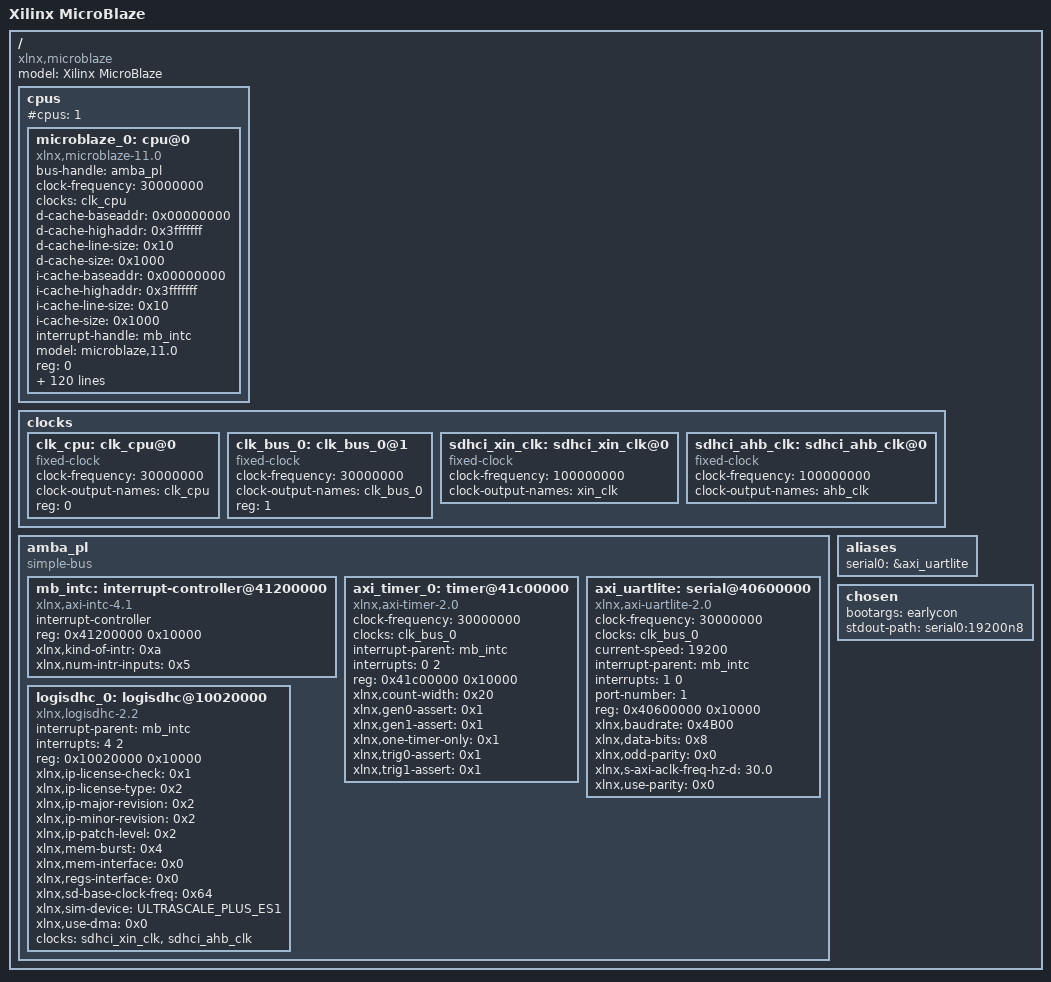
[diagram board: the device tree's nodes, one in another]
/*
 * This file is derived from the one which is automatically generated
 * from Xilinx Tools.
 * Version: XSCT
 * Today is: Fri May 10 15:45:01 2024
 */


/dts-v1/;
/ {
	#address-cells = <1>;
	#size-cells = <1>;
	compatible = "xlnx,microblaze";
	model = "Xilinx MicroBlaze";
	cpus {
		bootph-all;
		#address-cells = <1>;
		#cpus = <1>;
		#size-cells = <0>;
		microblaze_0: cpu@0 {
			bootph-all;
			bus-handle = <&amba_pl>;
			clock-frequency = <30000000>;
			clocks = <&clk_cpu>;
			compatible = "xlnx,microblaze-11.0";
			d-cache-baseaddr = <0x00000000>;
			d-cache-highaddr = <0x3fffffff>;
			d-cache-line-size = <0x10>;
			d-cache-size = <0x1000>;
			device_type = "cpu";
			i-cache-baseaddr = <0x00000000>;
			i-cache-highaddr = <0x3fffffff>;
			i-cache-line-size = <0x10>;
			i-cache-size = <0x1000>;
			interrupt-handle = <&mb_intc>;
			model = "microblaze,11.0";
			reg = <0>;
			timebase-frequency = <30000000>;
			xlnx,addr-size = <0x24>;
			xlnx,addr-tag-bits = <0x0>;
			xlnx,allow-dcache-wr = <0x1>;
			xlnx,allow-icache-wr = <0x1>;
			xlnx,area-optimized = <0x1>;
			xlnx,async-interrupt = <0x1>;
			xlnx,async-wakeup = <0x3>;
			xlnx,avoid-primitives = <0x0>;
			xlnx,base-vectors = <0x00000000 0x00000000>;
			xlnx,branch-target-cache-size = <0x0>;
			xlnx,cache-byte-size = <0x1000>;
			xlnx,d-axi = <0x1>;
			xlnx,d-lmb = <0x1>;
			xlnx,d-lmb-mon = <0x0>;
			xlnx,d-lmb-protocol = <0x0>;
			xlnx,daddr-size = <0x24>;
			xlnx,data-size = <0x20>;
			xlnx,dc-axi-mon = <0x0>;
			xlnx,dcache-addr-tag = <0x0>;
			xlnx,dcache-always-used = <0x1>;
			xlnx,dcache-byte-size = <0x1000>;
			xlnx,dcache-data-width = <0x0>;
			xlnx,dcache-force-tag-lutram = <0x0>;
			xlnx,dcache-line-len = <0x4>;
			xlnx,dcache-use-writeback = <0x0>;
			xlnx,dcache-victims = <0x0>;
			xlnx,debug-counter-width = <0x20>;
			xlnx,debug-enabled = <0x1>;
			xlnx,debug-event-counters = <0x5>;
			xlnx,debug-external-trace = <0x0>;
			xlnx,debug-interface = <0x0>;
			xlnx,debug-latency-counters = <0x1>;
			xlnx,debug-profile-size = <0x0>;
			xlnx,debug-trace-async-reset = <0x0>;
			xlnx,debug-trace-size = <0x2000>;
			xlnx,div-zero-exception = <0x0>;
			xlnx,dp-axi-mon = <0x0>;
			xlnx,dynamic-bus-sizing = <0x0>;
			xlnx,ecc-use-ce-exception = <0x0>;
			xlnx,edge-is-positive = <0x1>;
			xlnx,enable-discrete-ports = <0x0>;
			xlnx,endianness = <0x1>;
			xlnx,fault-tolerant = <0x0>;
			xlnx,fpu-exception = <0x0>;
			xlnx,freq = <0x1c9c380>;
			xlnx,fsl-exception = <0x0>;
			xlnx,fsl-links = <0x0>;
			xlnx,i-axi = <0x0>;
			xlnx,i-lmb = <0x1>;
			xlnx,i-lmb-mon = <0x0>;
			xlnx,i-lmb-protocol = <0x0>;
			xlnx,iaddr-size = <0x20>;
			xlnx,ic-axi-mon = <0x0>;
			xlnx,icache-always-used = <0x1>;
			xlnx,icache-data-width = <0x0>;
			xlnx,icache-force-tag-lutram = <0x0>;
			xlnx,icache-line-len = <0x4>;
			xlnx,icache-streams = <0x0>;
			xlnx,icache-victims = <0x0>;
			xlnx,ill-opcode-exception = <0x0>;
			xlnx,imprecise-exceptions = <0x0>;
			xlnx,instr-size = <0x20>;
			xlnx,interconnect = <0x2>;
			xlnx,interrupt-is-edge = <0x0>;
			xlnx,interrupt-mon = <0x0>;
			xlnx,ip-axi-mon = <0x0>;
			xlnx,lmb-data-size = <0x20>;
			xlnx,lockstep-master = <0x0>;
			xlnx,lockstep-select = <0x0>;
			xlnx,lockstep-slave = <0x0>;
			xlnx,mmu-dtlb-size = <0x2>;
			xlnx,mmu-itlb-size = <0x1>;
			xlnx,mmu-privileged-instr = <0x0>;
			xlnx,mmu-tlb-access = <0x3>;
			xlnx,mmu-zones = <0x2>;
			xlnx,num-sync-ff-clk = <0x2>;
			xlnx,num-sync-ff-clk-debug = <0x2>;
			xlnx,num-sync-ff-clk-irq = <0x1>;
			xlnx,num-sync-ff-dbg-clk = <0x1>;
			xlnx,num-sync-ff-dbg-trace-clk = <0x2>;
			xlnx,number-of-pc-brk = <0x1>;
			xlnx,number-of-rd-addr-brk = <0x0>;
			xlnx,number-of-wr-addr-brk = <0x0>;
			xlnx,opcode-0x0-illegal = <0x0>;
			xlnx,optimization = <0x0>;
			xlnx,pc-width = <0x20>;
			xlnx,piaddr-size = <0x20>;
			xlnx,pvr = <0x0>;
			xlnx,pvr-user1 = <0x00>;
			xlnx,pvr-user2 = <0x00000000>;
			xlnx,reset-msr = <0x00000000>;
			xlnx,reset-msr-bip = <0x0>;
			xlnx,reset-msr-dce = <0x0>;
			xlnx,reset-msr-ee = <0x0>;
			xlnx,reset-msr-eip = <0x0>;
			xlnx,reset-msr-ice = <0x0>;
			xlnx,reset-msr-ie = <0x0>;
			xlnx,sco = <0x0>;
			xlnx,temporal-depth = <0x0>;
			xlnx,trace = <0x0>;
			xlnx,unaligned-exceptions = <0x0>;
			xlnx,use-barrel = <0x1>;
			xlnx,use-branch-target-cache = <0x0>;
			xlnx,use-config-reset = <0x0>;
			xlnx,use-dcache = <0x0>;
			xlnx,use-div = <0x0>;
			xlnx,use-ext-brk = <0x0>;
			xlnx,use-ext-nm-brk = <0x0>;
			xlnx,use-extended-fsl-instr = <0x0>;
			xlnx,use-fpu = <0x0>;
			xlnx,use-hw-mul = <0x1>;
			xlnx,use-icache = <0x0>;
			xlnx,use-interrupt = <0x2>;
			xlnx,use-mmu = <0x0>;
			xlnx,use-msr-instr = <0x0>;
			xlnx,use-non-secure = <0x0>;
			xlnx,use-pcmp-instr = <0x1>;
			xlnx,use-reorder-instr = <0x0>;
			xlnx,use-stack-protection = <0x1>;
		};
	};
	clocks {
		bootph-all;
		#address-cells = <1>;
		#size-cells = <0>;
		clk_cpu: clk_cpu@0 {
			bootph-all;
			#clock-cells = <0>;
			clock-frequency = <30000000>;
			clock-output-names = "clk_cpu";
			compatible = "fixed-clock";
			reg = <0>;
		};
		clk_bus_0: clk_bus_0@1 {
			bootph-all;
			#clock-cells = <0>;
			clock-frequency = <30000000>;
			clock-output-names = "clk_bus_0";
			compatible = "fixed-clock";
			reg = <1>;
		};
                sdhci_xin_clk: sdhci_xin_clk@0 {
			bootph-all;
                        #clock-cells = <0x00>;
                        compatible = "fixed-clock";
                        clock-frequency = <100000000>;
                        clock-output-names = "xin_clk";
                };

                sdhci_ahb_clk: sdhci_ahb_clk@0 {
			bootph-all;
                        #clock-cells = <0x00>;
                        compatible = "fixed-clock";
                        clock-frequency = <100000000>;
                        clock-output-names = "ahb_clk";
                };
	};
	amba_pl: amba_pl {
		bootph-all;
		#address-cells = <1>;
		#size-cells = <1>;
		compatible = "simple-bus";
		ranges ;
		mb_intc: interrupt-controller@41200000 {
			bootph-all;
			#interrupt-cells = <2>;
			compatible = "xlnx,axi-intc-4.1", "xlnx,xps-intc-1.00.a";
			interrupt-controller ;
			reg = <0x41200000 0x10000>;
			xlnx,kind-of-intr = <0xa>;
			xlnx,num-intr-inputs = <0x5>;
		};
		axi_timer_0: timer@41c00000 {
			bootph-all;
			clock-frequency = <30000000>;
			clocks = <&clk_bus_0>;
			compatible = "xlnx,axi-timer-2.0", "xlnx,xps-timer-1.00.a";
			interrupt-names = "interrupt";
			interrupt-parent = <&mb_intc>;
			interrupts = <0 2>;
			reg = <0x41c00000 0x10000>;
			xlnx,count-width = <0x20>;
			xlnx,gen0-assert = <0x1>;
			xlnx,gen1-assert = <0x1>;
			xlnx,one-timer-only = <0x1>;
			xlnx,trig0-assert = <0x1>;
			xlnx,trig1-assert = <0x1>;
		};
		axi_uartlite: serial@40600000 {
			bootph-all;
			clock-frequency = <30000000>;
			clocks = <&clk_bus_0>;
			compatible = "xlnx,axi-uartlite-2.0", "xlnx,xps-uartlite-1.00.a";
			current-speed = <19200>;
			device_type = "serial";
			interrupt-names = "interrupt";
			interrupt-parent = <&mb_intc>;
			interrupts = <1 0>;
			port-number = <1>;
			reg = <0x40600000 0x10000>;
			xlnx,baudrate = <0x4B00>;
			xlnx,data-bits = <0x8>;
			xlnx,odd-parity = <0x0>;
			xlnx,s-axi-aclk-freq-hz-d = "30.0";
			xlnx,use-parity = <0x0>;
		};
		logisdhc_0: logisdhc@10020000 {
			bootph-all;
			compatible = "xlnx,logisdhc-2.2", "arasan,sdhci-8.9a";
			interrupt-names = "sd_int";
			interrupt-parent = <&mb_intc>;
			interrupts = <4 2>;
			reg = <0x10020000 0x10000>;
			xlnx,ip-license-check = <0x1>;
			xlnx,ip-license-type = <0x2>;
			xlnx,ip-major-revision = <0x2>;
			xlnx,ip-minor-revision = <0x2>;
			xlnx,ip-patch-level = <0x2>;
			xlnx,mem-burst = <0x4>;
			xlnx,mem-interface = <0x0>;
			xlnx,regs-interface = <0x0>;
			xlnx,sd-base-clock-freq = <0x64>;
			xlnx,sim-device = "ULTRASCALE_PLUS_ES1";
			xlnx,use-dma = <0x0>;
                        clock-names = "xin_clk", "ahb_clk";
                        clocks = <&sdhci_xin_clk>, <&sdhci_ahb_clk>;

		};
	};

        aliases {
                serial0 = &axi_uartlite;
        };
        chosen {
                bootargs = "earlycon";
                stdout-path = "serial0:19200n8";
        };
};
